# USI_1 register map
Vendor: Texas Instruments
Peripheral module from a debugger description file (folder msp430).
Registers are 8-bit, access not given, no defined reset value unless marked. A register's access mark holds for its fields unless they carry their own. Offsets are as the file gives them; lines under a group give offsets from that group; [hi:lo] are bit positions; {n}, {i} and the like mark numbered series; 'fields as' and 'values as' point back to an identical list; <NAME> marks a mode.

## USI
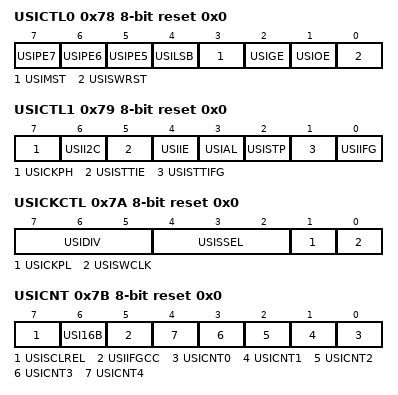
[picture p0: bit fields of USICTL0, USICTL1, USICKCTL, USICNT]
0x78 USICTL0 rw reset 0x0 — USI Control Register 0
  [7] USIPE7 — USI Port Enable Px.7
  [6] USIPE6 — USI Port Enable Px.6
  [5] USIPE5 — USI Port Enable Px.5
  [4] USILSB — USI LSB first 1:LSB / 0:MSB
  [3] USIMST — USI Master Select 0:Slave / 1:Master
  [2] USIGE — USI General Output Enable Latch
  [1] USIOE — USI Output Enable
  [0] USISWRST — USI Software Reset
0x78 USICTL 16-bit — USI Control Register
0x79 USICTL1 rw reset 0x0 — USI Control Register 1
  [7] USICKPH — USI Sync. Mode: Clock Phase
  [6] USII2C — USI I2C Mode
  [5] USISTTIE — USI START Condition interrupt enable
  [4] USIIE — USI Counter Interrupt enable
  [3] USIAL — USI Arbitration Lost
  [2] USISTP — USI STOP Condition received
  [1] USISTTIFG — USI START Condition interrupt Flag
  [0] USIIFG — USI Counter Interrupt Flag
0x7A USICKCTL rw reset 0x0 — USI Clock Control Register
  [7:5] USIDIV — USI Clock Divider 2
    {v}=USI Clock Divider: {v} (v=0..7)
  [4:2] USISSEL — USI Clock Source Select 2
    {v}=USI Clock Source: {v} (v=0..7)
  [1] USICKPL — USI Clock Polarity 0:Inactive=Low / 1:Inactive=High
  [0] USISWCLK — USI Software Clock
0x7A USICCTL 16-bit — USI Clock and Counter Control Register
0x7B USICNT rw reset 0x0 — USI Bit Counter Register
  [7] USISCLREL — USI SCL Released
  [6] USI16B — USI 16 Bit Shift Register Enable
  [5] USIIFGCC — USI Interrupt Flag Clear Control
  [n] USICNT{n} (n=0..4) — USI Bit Count {n}
0x7C USISRL — USI Low Byte Shift Register
0x7C USISR 16-bit — USI Shift Register
0x7D USISRH — USI High Byte Shift Register
